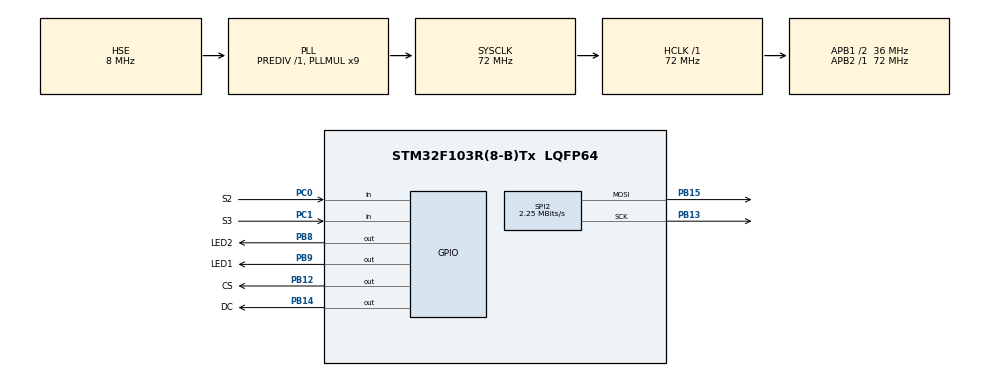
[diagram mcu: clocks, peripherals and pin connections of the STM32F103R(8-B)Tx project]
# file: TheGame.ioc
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Dma.Request0=SPI2_TX
Dma.SPI2_TX.0.Direction=DMA_MEMORY_TO_PERIPH
Dma.SPI2_TX.0.Instance=DMA1_Channel5
Dma.SPI2_TX.0.MemDataAlignment=DMA_MDATAALIGN_BYTE
Dma.SPI2_TX.0.MemInc=DMA_MINC_ENABLE
Dma.SPI2_TX.0.Mode=DMA_NORMAL
Dma.SPI2_TX.0.PeriphDataAlignment=DMA_PDATAALIGN_BYTE
Dma.SPI2_TX.0.PeriphInc=DMA_PINC_DISABLE
Dma.SPI2_TX.0.Priority=DMA_PRIORITY_LOW
Mcu.Family=STM32F1
Mcu.Name=STM32F103R(8-B)Tx
Mcu.Package=LQFP64
NVIC.DMA1_Channel5_IRQn=true\:0\:0\:false
NVIC.PriorityGroup=NVIC_PRIORITYGROUP_4
PA13.Mode=Serial_Wire
PA13.Signal=SYS_JTMS-SWDIO
PA14.Mode=Serial_Wire
PA14.Signal=SYS_JTCK-SWCLK
PB12.GPIO_Label=CS
PB12.GPIO_ModeDefaultOutputPP=GPIO_MODE_OUTPUT_PP
PB12.GPIO_Speed=GPIO_SPEED_HIGH
PB12.Signal=GPIO_Output
PB13.Mode=TX_Only_Simplex_Unidirect_Master
PB13.Signal=SPI2_SCK
PB14.GPIO_Label=DC
PB14.GPIO_ModeDefaultOutputPP=GPIO_MODE_OUTPUT_PP
PB14.GPIO_Speed=GPIO_SPEED_HIGH
PB14.Signal=GPIO_Output
PB15.Mode=TX_Only_Simplex_Unidirect_Master
PB15.Signal=SPI2_MOSI
PB8.GPIO_Label=LED2
PB8.GPIO_ModeDefaultOutputPP=GPIO_MODE_OUTPUT_PP
PB8.GPIO_Speed=GPIO_SPEED_LOW
PB8.Signal=GPIO_Output
PB9.GPIO_Label=LED1
PB9.GPIO_ModeDefaultOutputPP=GPIO_MODE_OUTPUT_PP
PB9.GPIO_Speed=GPIO_SPEED_LOW
PB9.Signal=GPIO_Output
PC0.GPIO_Label=S2
PC0.GPIO_Mode=GPIO_MODE_INPUT
PC0.GPIO_PuPd=GPIO_NOPULL
PC0.Signal=GPIO_Input
PC1.GPIO_Label=S3
PC1.GPIO_Mode=GPIO_MODE_INPUT
PC1.GPIO_PuPd=GPIO_NOPULL
PC1.Signal=GPIO_Input
PD0-OSC_IN.Mode=HSE-External-Oscillator
PD0-OSC_IN.Signal=RCC_OSC_IN
PD1-OSC_OUT.Mode=HSE-External-Oscillator
PD1-OSC_OUT.Signal=RCC_OSC_OUT
ProjectManager.HeapSize=0x200
ProjectManager.StackSize=0x400
ProjectManager.TargetToolchain=MDK-ARM V5
RCC.AHBFreq_Value=72000000
RCC.APB1CLKDivider=RCC_HCLK_DIV2
RCC.APB1Freq_Value=36000000
RCC.APB1TimFreq_Value=72000000
RCC.APB2Freq_Value=72000000
RCC.APB2TimFreq_Value=72000000
RCC.HCLKFreq_Value=72000000
RCC.HSIState=RCC_HSI_ON
RCC.PLLMUL=RCC_PLL_MUL9
RCC.PLLSourceVirtual=RCC_PLLSOURCE_HSE
RCC.SYSCLKFreq_VALUE=72000000
RCC.SYSCLKSource=RCC_SYSCLKSOURCE_PLLCLK
RCC.USBFreq_Value=72000000
SPI2.BaudRatePrescaler=SPI_BAUDRATEPRESCALER_16
SPI2.CalculateBaudRate=2.25 MBits/s
SPI2.Mode=SPI_MODE_MASTER
VP_CRC_VS_CRC.Mode=CRC_Activate
board=TheGame

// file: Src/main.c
/**
  ******************************************************************************
  * File Name          : main.c
  * Description        : Main program body
  ******************************************************************************
  *
  * COPYRIGHT(c) 2015 STMicroelectronics
  *
  * Redistribution and use in source and binary forms, with or without modification,
  * are permitted provided that the following conditions are met:
  *   1. Redistributions of source code must retain the above copyright notice,
  *      this list of conditions and the following disclaimer.
  *   2. Redistributions in binary form must reproduce the above copyright notice,
  *      this list of conditions and the following disclaimer in the documentation
  *      and/or other materials provided with the distribution.
  *   3. Neither the name of STMicroelectronics nor the names of its contributors
  *      may be used to endorse or promote products derived from this software
  *      without specific prior written permission.
  *
  * THIS SOFTWARE IS PROVIDED BY THE COPYRIGHT HOLDERS AND CONTRIBUTORS "AS IS"
  * AND ANY EXPRESS OR IMPLIED WARRANTIES, INCLUDING, BUT NOT LIMITED TO, THE
  * IMPLIED WARRANTIES OF MERCHANTABILITY AND FITNESS FOR A PARTICULAR PURPOSE ARE
  * DISCLAIMED. IN NO EVENT SHALL THE COPYRIGHT HOLDER OR CONTRIBUTORS BE LIABLE
  * FOR ANY DIRECT, INDIRECT, INCIDENTAL, SPECIAL, EXEMPLARY, OR CONSEQUENTIAL
  * DAMAGES (INCLUDING, BUT NOT LIMITED TO, PROCUREMENT OF SUBSTITUTE GOODS OR
  * SERVICES; LOSS OF USE, DATA, OR PROFITS; OR BUSINESS INTERRUPTION) HOWEVER
  * CAUSED AND ON ANY THEORY OF LIABILITY, WHETHER IN CONTRACT, STRICT LIABILITY,
  * OR TORT (INCLUDING NEGLIGENCE OR OTHERWISE) ARISING IN ANY WAY OUT OF THE USE
  * OF THIS SOFTWARE, EVEN IF ADVISED OF THE POSSIBILITY OF SUCH DAMAGE.
  *
  ******************************************************************************
  */
#include "stm32f1xx_hal.h"
#include "ssd1306.h"

CRC_HandleTypeDef hcrc;

SPI_HandleTypeDef hspi2;
DMA_HandleTypeDef hdma_spi2_tx;

/* USER CODE BEGIN PV */
/* Private variables ---------------------------------------------------------*/

/* USER CODE END PV */

void SystemClock_Config(void);
static void MX_GPIO_Init(void);
static void MX_DMA_Init(void);
static void MX_CRC_Init(void);
static void MX_SPI2_Init(void);

/* USER CODE BEGIN PFP */
/* Private function prototypes -----------------------------------------------*/
extern void SSD1306LibTest();
/* USER CODE END PFP */

int main(void)
{

  /* MCU Configuration----------------------------------------------------------*/

  /* Reset of all peripherals, Initializes the Flash interface and the Systick. */
  HAL_Init();

  /* Configure the system clock */
  SystemClock_Config();

  /* Initialize all configured peripherals */
  MX_GPIO_Init();
  MX_DMA_Init();
  MX_CRC_Init();
  MX_SPI2_Init();

  /* USER CODE BEGIN 2 */
  ssd1306Init(SSD1306_CHARGEPUMP);
  ssd1306ClearScreen( LAYER0 | LAYER1 );
  ssd1306Refresh();
  HAL_Delay(100);
  /* USER CODE END 2 */

  /* Infinite loop */
  while (1)
  {

  /* USER CODE BEGIN 3 */
		SSD1306LibTest();
  }
  /* USER CODE END 3 */

}

/** System Clock Configuration
*/
void SystemClock_Config(void)
{

  RCC_OscInitTypeDef RCC_OscInitStruct;
  RCC_ClkInitTypeDef RCC_ClkInitStruct;

  RCC_OscInitStruct.OscillatorType = RCC_OSCILLATORTYPE_HSE;
  RCC_OscInitStruct.HSEState = RCC_HSE_ON;
  RCC_OscInitStruct.HSEPredivValue = RCC_HSE_PREDIV_DIV1;
  RCC_OscInitStruct.PLL.PLLState = RCC_PLL_ON;
  RCC_OscInitStruct.PLL.PLLSource = RCC_PLLSOURCE_HSE;
  RCC_OscInitStruct.PLL.PLLMUL = RCC_PLL_MUL9;
  HAL_RCC_OscConfig(&RCC_OscInitStruct);

  RCC_ClkInitStruct.ClockType = RCC_CLOCKTYPE_SYSCLK|RCC_CLOCKTYPE_PCLK1;
  RCC_ClkInitStruct.SYSCLKSource = RCC_SYSCLKSOURCE_PLLCLK;
  RCC_ClkInitStruct.AHBCLKDivider = RCC_SYSCLK_DIV1;
  RCC_ClkInitStruct.APB1CLKDivider = RCC_HCLK_DIV2;
  RCC_ClkInitStruct.APB2CLKDivider = RCC_HCLK_DIV1;
  HAL_RCC_ClockConfig(&RCC_ClkInitStruct, FLASH_LATENCY_2);

  HAL_SYSTICK_Config(HAL_RCC_GetHCLKFreq()/1000);

  HAL_SYSTICK_CLKSourceConfig(SYSTICK_CLKSOURCE_HCLK);

  /* SysTick_IRQn interrupt configuration */
  HAL_NVIC_SetPriority(SysTick_IRQn, 0, 0);
}

/* CRC init function */
void MX_CRC_Init(void)
{

  hcrc.Instance = CRC;
  HAL_CRC_Init(&hcrc);

}

/* SPI2 init function */
void MX_SPI2_Init(void)
{

  hspi2.Instance = SPI2;
  hspi2.Init.Mode = SPI_MODE_MASTER;
  hspi2.Init.Direction = SPI_DIRECTION_2LINES;
  hspi2.Init.DataSize = SPI_DATASIZE_8BIT;
  hspi2.Init.CLKPolarity = SPI_POLARITY_LOW;
  hspi2.Init.CLKPhase = SPI_PHASE_1EDGE;
  hspi2.Init.NSS = SPI_NSS_SOFT;
  hspi2.Init.BaudRatePrescaler = SPI_BAUDRATEPRESCALER_16;
  hspi2.Init.FirstBit = SPI_FIRSTBIT_MSB;
  hspi2.Init.TIMode = SPI_TIMODE_DISABLED;
  hspi2.Init.CRCCalculation = SPI_CRCCALCULATION_DISABLED;
  hspi2.Init.CRCPolynomial = 10;
  HAL_SPI_Init(&hspi2);

}

void MX_DMA_Init(void)
{
  /* DMA controller clock enable */
  __HAL_RCC_DMA1_CLK_ENABLE();

  /* DMA interrupt init */
  HAL_NVIC_SetPriority(DMA1_Channel5_IRQn, 0, 0);
  HAL_NVIC_EnableIRQ(DMA1_Channel5_IRQn);

}

/** Configure pins as
        * Analog
        * Input
        * Output
        * EVENT_OUT
        * EXTI
*/
void MX_GPIO_Init(void)
{

  GPIO_InitTypeDef GPIO_InitStruct;

  /* GPIO Ports Clock Enable */
  __GPIOD_CLK_ENABLE();
  __GPIOC_CLK_ENABLE();
  __GPIOB_CLK_ENABLE();
  __GPIOA_CLK_ENABLE();

  /*Configure GPIO pins : S2_Pin S3_Pin */
  GPIO_InitStruct.Pin = S2_Pin|S3_Pin;
  GPIO_InitStruct.Mode = GPIO_MODE_INPUT;
  GPIO_InitStruct.Pull = GPIO_NOPULL;
  HAL_GPIO_Init(GPIOC, &GPIO_InitStruct);

  /*Configure GPIO pins : CS_Pin DC_Pin */
  GPIO_InitStruct.Pin = CS_Pin|DC_Pin;
  GPIO_InitStruct.Mode = GPIO_MODE_OUTPUT_PP;
  GPIO_InitStruct.Speed = GPIO_SPEED_HIGH;
  HAL_GPIO_Init(GPIOB, &GPIO_InitStruct);

  /*Configure GPIO pins : LED2_Pin LED1_Pin */
  GPIO_InitStruct.Pin = LED2_Pin|LED1_Pin;
  GPIO_InitStruct.Mode = GPIO_MODE_OUTPUT_PP;
  GPIO_InitStruct.Speed = GPIO_SPEED_LOW;
  HAL_GPIO_Init(GPIOB, &GPIO_InitStruct);

}

/************************ (C) COPYRIGHT STMicroelectronics *****END OF FILE****/
